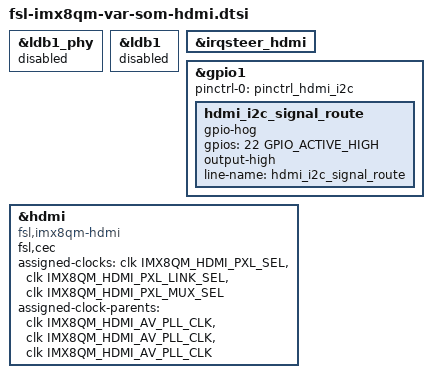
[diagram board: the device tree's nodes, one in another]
/*
 * Copyright 2019 Variscite Ltd.
 *
 * This program is free software; you can redistribute it and/or
 * modify it under the terms of the GNU General Public License
 * as published by the Free Software Foundation; either version 2
 * of the License, or (at your option) any later version.
 *
 * This program is distributed in the hope that it will be useful,
 * but WITHOUT ANY WARRANTY; without even the implied warranty of
 * MERCHANTABILITY or FITNESS FOR A PARTICULAR PURPOSE.  See the
 * GNU General Public License for more details.
 */


&ldb1_phy {
	status = "disabled";
};

&ldb1 {
	status = "disabled";
};

&irqsteer_hdmi {
	status = "okay";
};

&gpio1 {
        pinctrl-names = "default";
        pinctrl-0 = <&pinctrl_hdmi_i2c>;

        hdmi_i2c_signal_route {
                gpio-hog;
                gpios = <22 GPIO_ACTIVE_HIGH>;
                output-high;
                line-name = "hdmi_i2c_signal_route";
        };
};

&hdmi {
       compatible = "fsl,imx8qm-hdmi";
       fsl,cec;
       assigned-clocks = <&clk IMX8QM_HDMI_PXL_SEL>,
                         <&clk IMX8QM_HDMI_PXL_LINK_SEL>,
                         <&clk IMX8QM_HDMI_PXL_MUX_SEL>;
       assigned-clock-parents = <&clk IMX8QM_HDMI_AV_PLL_CLK>,
                                <&clk IMX8QM_HDMI_AV_PLL_CLK>,
                                <&clk IMX8QM_HDMI_AV_PLL_CLK>;
       status = "okay";
};
